# EOS-S3 register map
File version: 0.1
CPU: CM4 r0p1, selectable endian, MPU, FPU, 3 interrupt priority bits
Registers are 32-bit, read-write, reset 0x0 unless marked. A register's access mark holds for its fields unless they carry their own. Offsets are from the block's base; [hi:lo] are bit positions; {n}, {i} and the like mark numbered series.

## AUD — Audio Subsystem
Base 0x40015000
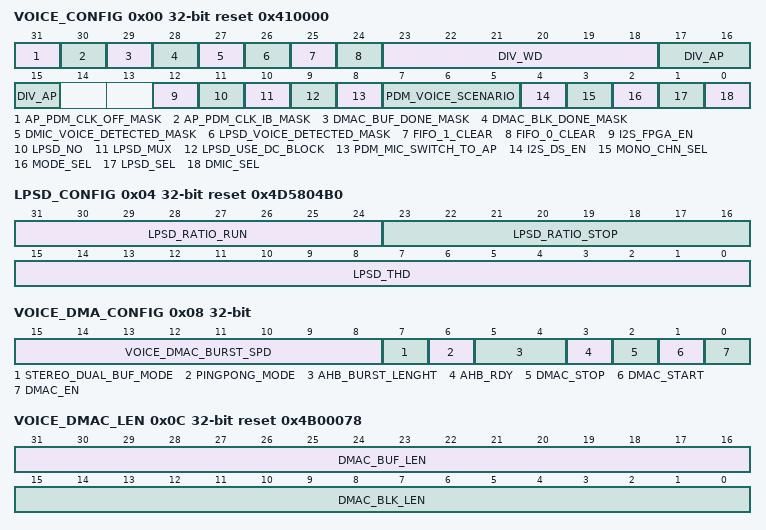
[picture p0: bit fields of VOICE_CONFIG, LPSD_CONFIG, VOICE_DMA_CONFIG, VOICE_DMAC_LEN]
0x00 VOICE_CONFIG reset 0x410000 — Audio system configure register
  [31] AP_PDM_CLK_OFF_MASK — Control the masking of the interrupt
    0=Unmask the interrupt; 1=Mask the interrupt
  [30] AP_PDM_CLK_IB_MASK — Control the masking of the interrupt
    0=Unmask the interrupt; 1=Mask the interrupt
  [29] DMAC_BUF_DONE_MASK — Control the masking of the interrupt
    0=Unmask the interrupt; 1=Mask the interrupt
  [28] DMAC_BLK_DONE_MASK — Control the masking of the interrupt
    0=Unmask the interrupt; 1=Mask the interrupt
  [27] DMIC_VOICE_DETECTED_MASK — Control the masking of the interrupt
    0=Unmask the interrupt; 1=Mask the interrupt
  [26] LPSD_VOICE_DETECTED_MASK — Control the masking of the interrupt
    0=Unmask the interrupt; 1=Mask the interrupt
  [25] FIFO_1_CLEAR — Set to Flush FIFO
  [24] FIFO_0_CLEAR — Set to flush FIFO
  [23:18] DIV_WD — AP_PDM_CKO_IN clock detection window range
  [17:15] DIV_AP — AP_PDM_CKO_IN frequency divide-down ratio for AP clock detection
  [12] I2S_FPGA_EN — Set to enable the FPGA I2S
  [11] LPSD_NO — Set to disable HW LPSD
    0=enable_hw (Enable hardware LPSD); 1=Disable HW LPSD
  [10] LPSD_MUX — Choose the channel pcm data for LPSD in stereo mode
    0=Left channel pcm data to LPSD in stereo mode; 1=Right channel pcm data to LPSD in stereo mode
  [9] LPSD_USE_DC_BLOCK — Set to use LPSD DC Block
  [8] PDM_MIC_SWITCH_TO_AP — Set to switch mic to AP
    0=no_switch (Don't switch to AP); 1=Switch to AP
  [7:5] PDM_VOICE_SCENARIO — Choose the PDM voice scenario
    0=scenario1 (Choose voice scenario 1); 1=scenario2 (Choose voice scenario 2); 2=scenario3_mode1 (Choose voice scenario 3 mode 1); 3=scenario3_mode2 (Choose voice scenario 3 mode 2); 4=scenario3_mode3 (Choose voice scenario 3 mode 3)
  [4] I2S_DS_EN — Set to enable the I2S Deep Sleep mode
  [3] MONO_CHN_SEL — Select either right channel in mono mode or left channel
    0=Left channel in mono mode; 1=Right channel in mono mode
  [2] MODE_SEL — Select either monoaural or stereo mode
    0=mono (Audio mode selected as Mono); 1=stereo (Audio mode selected as Stereo)
  [1] LPSD_SEL — Select between external or internal sensory LSPD
    0=internal (Use internal sensory LPSD); 1=external (Use external sensory LPSD)
  [0] DMIC_SEL — Select the source for digital mic signal
    0=pdm (DMIC source is PDM); 1=i2s (DMIC source is I2S)
0x04 LPSD_CONFIG reset 0x4D5804B0
  [31:24] LPSD_RATIO_RUN — LPSD run parameter
  [23:16] LPSD_RATIO_STOP — LPSD threshold parameter
  [15:0] LPSD_THD — LPSD threshold parameter
0x08 VOICE_DMA_CONFIG — Audio DMAC configure register
  [15:8] VOICE_DMAC_BURST_SPD — AHB cycles between two consecutive AHB Bursts
  [7] STEREO_DUAL_BUF_MODE — Select how to process stereo buffer data
  [6] PINGPONG_MODE — Select the pingpong mode
  [5:4] AHB_BURST_LENGHT — Select the AHB Burst Lenght in words
  [3] AHB_RDY — Set to indicate AHB clock is ready
  [2] DMAC_STOP — Set to Stop DMA
  [1] DMAC_START wo — Set to start DMA
  [0] DMAC_EN — Set to enable Voice DMAC
0x0C VOICE_DMAC_LEN reset 0x4B00078 — Audio DMAC length register
  [31:16] DMAC_BUF_LEN — DMA buffer transfer length in words
  [15:0] DMAC_BLK_LEN — DMA block transfer length in words
0x10 VOICE_DMAC_FIFO — Audio DMAC Buffer offset
  [31:16] DMAC_BUF_OFFSER — buffer offset address in dual buffer mode
0x14 VOICE_DMAC_DST_ADDR0 — DMA0 dest address for the first buffer
0x18 VOICE_DMAC_DST_ADDR1 — DMA1 dest address for the first buffer
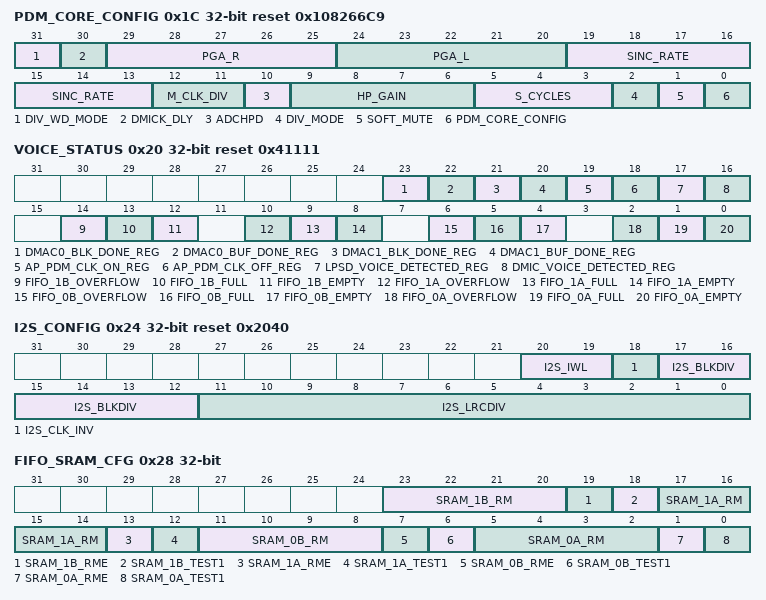
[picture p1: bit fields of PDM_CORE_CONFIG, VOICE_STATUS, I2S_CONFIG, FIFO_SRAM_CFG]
0x1C PDM_CORE_CONFIG reset 0x108266C9 — PDM2PCM core configure register
  [31] DIV_WD_MODE — Status IN detection windows
  [30] DMICK_DLY — Input data sampling with PDM clock cycle delay
  [29:25] PGA_R — Right channel PGA gain
  [24:20] PGA_L — Left channel PGA gain
  [19:13] SINC_RATE — SINC decimation rate
  [12:11] M_CLK_DIV — PDM_CLK frquency divisor
  [10] ADCHPD — Set to disable high pass filter
  [9:6] HP_GAIN — Adjust high pass filter coefficients
  [5:3] S_CYCLES — Set number of PDM_CLK during gain setting changes or soft mute
  [2] DIV_MODE — Select which divider to use in sampler
    0=left (Use PDM_LEFT in sampler); 1=right (Use PDM_RIGHT in sampler)
  [1] SOFT_MUTE — Set to enable PDM Soft mute
  [0] PDM_CORE_CONFIG — Set to enable PDM core
0x20 VOICE_STATUS reset 0x41111 — Audio Status Register
  [23] DMAC0_BLK_DONE_REG — Set if done
  [22] DMAC0_BUF_DONE_REG — Set if done
  [21] DMAC1_BLK_DONE_REG — Set if done
  [20] DMAC1_BUF_DONE_REG — Set if done
  [19] AP_PDM_CLK_ON_REG ro — Set if AP PDM clock is on
  [18] AP_PDM_CLK_OFF_REG ro — Set if AP PDM clock is off
  [17] LPSD_VOICE_DETECTED_REG ro — Set if detected
  [16] DMIC_VOICE_DETECTED_REG ro — Set if detected
  [14] FIFO_1B_OVERFLOW — Set if there's a FIFO overflow
  [13] FIFO_1B_FULL — Set if the FIFO is full
  [12] FIFO_1B_EMPTY ro — Set if the FIFO is empty
  [10] FIFO_1A_OVERFLOW — Set if there's a FIFO overflow
  [9] FIFO_1A_FULL — Set if the FIFO is full
  [8] FIFO_1A_EMPTY ro — Set if the FIFO is empty
  [6] FIFO_0B_OVERFLOW — Set if there's a FIFO overflow
  [5] FIFO_0B_FULL — Set if the FIFO is full
  [4] FIFO_0B_EMPTY ro — Set if the FIFO is empty
  [2] FIFO_0A_OVERFLOW — Set if there's a FIFO overflow
  [1] FIFO_0A_FULL — Set if the FIFO is full
  [0] FIFO_0A_EMPTY ro — Set if the FIFO is empty
0x24 I2S_CONFIG reset 0x2040 — I2S master configure register
  [20:19] I2S_IWL — Input sample data bit shift
  [18] I2S_CLK_INV — Set to activate inverting
  [17:12] I2S_BLKDIV — I2S_MASTER_CLK divisor for I2S_CLK generator
  [11:0] I2S_LRCDIV — I2S_CLK divisor for WD_CLK generator
0x28 FIFO_SRAM_CFG — FIFO SRAM configure register
  [23:20] SRAM_1B_RM — Read-Write margin Input for Right Channel 512B FIFO
  [19] SRAM_1B_RME — Read-Write margin Enable input
  [18] SRAM_1B_TEST1 — Test pin to bypass self-timed circuit
  [17:14] SRAM_1A_RM — Read-Write margin Input for Right Channel 8KB FIFO
  [13] SRAM_1A_RME — Read-Write margin Enable input
  [12] SRAM_1A_TEST1 — Test pin to bypass self-timed circuit
  [11:8] SRAM_0B_RM — Read-Write margin Input for Left Channel 512B FIFO
  [7] SRAM_0B_RME — Read-Write margin Enable input
  [6] SRAM_0B_TEST1 — Test pin to bypass self-timed circuit
  [5:2] SRAM_0A_RM — Read-Write margin Input for Left Channel 8KB FIFO
  [1] SRAM_0A_RME — Read-Write margin Enable input
  [0] SRAM_0A_TEST1 — Test pin to bypass self-timed circuit
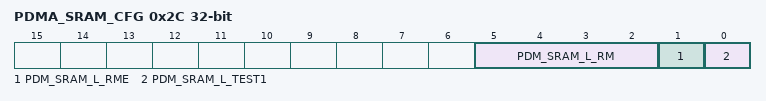
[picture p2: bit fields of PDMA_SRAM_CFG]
0x2C PDMA_SRAM_CFG — PDM core SRAM configure register
  [5:2] PDM_SRAM_L_RM — Read-Write margin Input for Right Channel PDM SRAM
  [1] PDM_SRAM_L_RME — Read-Write margin Enable Input
  [0] PDM_SRAM_L_TEST1 — Test pin to bypass self-timed circuit
0x30 DBG_MUX_CFG — Audio Debug Register
  [3:0] DBG_MUX — 0000 => dbg_tp[7:0] = dbg_fifo_0a_wptr[7:0]. 0001 => dbg_tp[7:0] = dbg_fifo_0a_rptr[7:0]. 0010 => dbg_tp[7:0] = {1'b0, dbg_fifo_0a_rptr[10:8], 1'b0, dbg_fifo_0a_wptr[10:8]} . 0011 => dbg_tp[7:0] = dbg_fifo_1a_wptr[7:0]. 0100 => dbg_tp[7:0] = dbg_fifo_1a_rptr[7:0]. 0101 => dbg_tp[7:0] = {1'b0, dbg_fifo_1a_rptr[10:8], 1'b0, dbg_fifo_1a_wptr[10:8]} . 0110 => dbg_tp[7:0] = {2'd0, dbg_fifo_0b_wptr[5:0]} . 0111 => dbg_tp[7:0] = {2'd0, dbg_fifo_0b_rptr[5:0]} . 1000 => dbg_tp[7:0] = {2'd0, dbg_fifo_1b_wptr[5:0]} . 1001 => dbg_tp[7:0] = {2'd0, dbg_fifo_1b_rptr[5:0]} . 1010 => dbg_tp[7:0] = {2'd0, dbg_afifo_0_rptr[1:0], 2'd0, dbg_afifo_0_wptr[1:0]} . 1011 => dbg_tp[7:0] ={2'd0, dbg_afifo_1_rptr[1:0], 2'd0, dbg_afifo_1_wptr[1:0]} . 1100 => dbg_tp[7:0] = {PCM_DATA_L[7:1],VALID} . 1101 => dbg_tp[7:0] = {PCM_DATA_L[15:9],VALID} . 1110 => dbg_tp[7:0] = {PCM_DATA_R[7:1],VALID} . 1111 => dbg_tp[7:0] = {PCM_DATA_R[15:9],VALID}
